VERSION ""

NS_ :

BS_:

BU_:

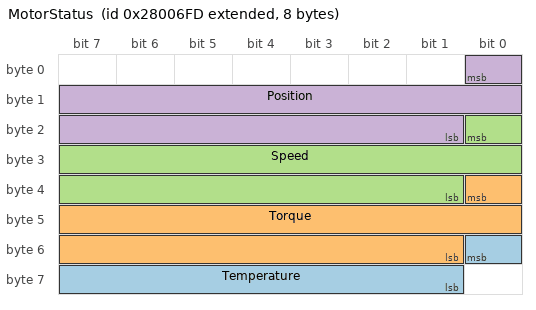
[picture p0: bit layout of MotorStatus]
BO_ 2189428477 MotorStatus: 8 Vector__XXX
 SG_ Temperature : 48|8@0- (1,0) [0|0] "°C" Vector__XXX
 SG_ Torque : 32|16@0- (1,0) [0|0] "Nm" Vector__XXX
 SG_ Speed : 16|16@0- (1,0) [0|0] "rad/s" Vector__XXX
 SG_ Position : 0|16@0- (1,0) [0|0] "rad" Vector__XXX
